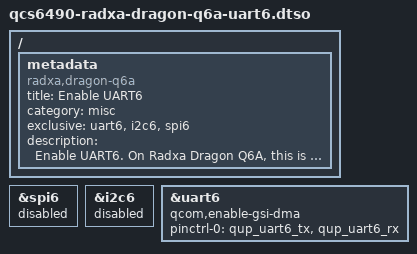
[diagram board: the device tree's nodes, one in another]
// SPDX-License-Identifier: BSD-3-Clause
/*
 * Copyright (c) 2025 Radxa Computer (Shenzhen) Co., Ltd.
 */

/dts-v1/;
/plugin/;

/ {
    metadata {
        title = "Enable UART6";
        compatible = "radxa,dragon-q6a";
        category = "misc";
        exclusive = "uart6","i2c6","spi6";
        description = "Enable UART6. 
On Radxa Dragon Q6A, this is pin 16(tx), 18(rx).";
    };
};

&spi6 {
	status = "disabled";
};

&i2c6 {
	status = "disabled";
};

&uart6 {
	qcom,enable-gsi-dma;
	status = "okay";
    pinctrl-0 = <&qup_uart6_tx>, <&qup_uart6_rx>;
};
